# 3067M register map
File version: 1.0
Registers are 32-bit, access per field, reset 0x0 unless marked. A register's access mark holds for its fields unless they carry their own. Offsets are from the block's base; [hi:lo] are bit positions; {n}, {i} and the like mark numbered series.

## IOCMG_AON — IOCMG_AON peripheral interface
Base 0x147F0000
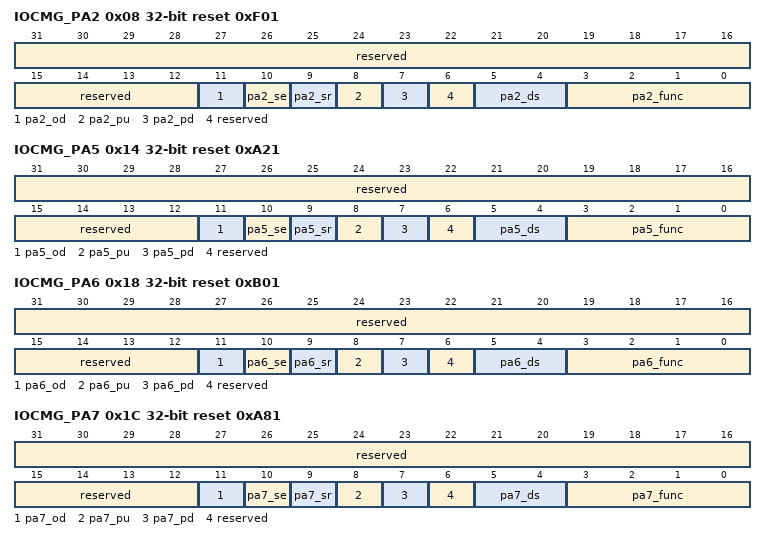
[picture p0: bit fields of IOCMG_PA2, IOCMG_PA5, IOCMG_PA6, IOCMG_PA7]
0x08 IOCMG_PA2 reset 0xF01 — IOCMG_PA2为PA2管脚控制寄存器。
  [31:12] reserved ro — 保留。
  [11] pa2_od rw — 管脚开漏输出控制。 0：打开； 1：关闭。
  [10] pa2_se rw — 管脚施密特输入控制。 0：关闭； 1：打开。
  [9] pa2_sr rw — 管脚电平转换速率控制。 0：快沿输出； 1：慢沿输出。
  [8] pa2_pu rw — 管脚上拉控制。 0：关闭； 1：打开。
  [7] pa2_pd rw — 管脚下拉控制。 0：关闭； 1：打开。
  [6] reserved ro — 保留。
  [5:4] pa2_ds rw — 管脚驱动能力选择（档位越高，驱动能力越大）。 00：档位1； 01：档位2； 10：档位3； 11：档位4。
  [3:0] pa2_func rw — 管脚复用功能选择。 具体复用功能请参见《3066H系列数据手册》。
0x14 IOCMG_PA5 reset 0xA21 — IOCMG_PA5为PA5管脚控制寄存器。
  [31:12] reserved ro — 保留。
  [11] pa5_od rw — 管脚开漏输出控制。 0：打开； 1：关闭。
  [10] pa5_se rw — 管脚施密特输入控制。 0：关闭； 1：打开。
  [9] pa5_sr rw — 管脚电平转换速率控制。 0：快沿输出； 1：慢沿输出。
  [8] pa5_pu rw — 管脚上拉控制。 0：关闭； 1：打开。
  [7] pa5_pd rw — 管脚下拉控制。 0：关闭； 1：打开。
  [6] reserved ro — 保留。
  [5:4] pa5_ds rw — 管脚驱动能力选择（档位越高，驱动能力越大）。 00：档位1； 01：档位2； 10：档位3； 11：档位4。
  [3:0] pa5_func rw — 管脚复用功能选择。 具体复用功能请参见《3066H系列数据手册》。
0x18 IOCMG_PA6 reset 0xB01 — IOCMG_PA6为PA6管脚控制寄存器。
  [31:12] reserved ro — 保留。
  [11] pa6_od rw — 管脚开漏输出控制。 0：打开； 1：关闭。
  [10] pa6_se rw — 管脚施密特输入控制。 0：关闭； 1：打开。
  [9] pa6_sr rw — 管脚电平转换速率控制。 0：快沿输出； 1：慢沿输出。
  [8] pa6_pu rw — 管脚上拉控制。 0：关闭； 1：打开。
  [7] pa6_pd rw — 管脚下拉控制。 0：关闭； 1：打开。
  [6] reserved ro — 保留。
  [5:4] pa6_ds rw — 管脚驱动能力选择（档位越高，驱动能力越大）。 00：档位1； 01：档位2； 10：档位3； 11：档位4。
  [3:0] pa6_func rw — 管脚复用功能选择。 具体复用功能请参见《3066H系列数据手册》。
0x1C IOCMG_PA7 reset 0xA81 — IOCMG_PA7为PA7管脚控制寄存器。
  [31:12] reserved ro — 保留。
  [11] pa7_od rw — 管脚开漏输出控制。 0：打开； 1：关闭。
  [10] pa7_se rw — 管脚施密特输入控制。 0：关闭； 1：打开。
  [9] pa7_sr rw — 管脚电平转换速率控制。 0：快沿输出； 1：慢沿输出。
  [8] pa7_pu rw — 管脚上拉控制。 0：关闭； 1：打开。
  [7] pa7_pd rw — 管脚下拉控制。 0：关闭； 1：打开。
  [6] reserved ro — 保留。
  [5:4] pa7_ds rw — 管脚驱动能力选择（档位越高，驱动能力越大）。 00：档位1； 01：档位2； 10：档位3； 11：档位4。
  [3:0] pa7_func rw — 管脚复用功能选择。 具体复用功能请参见《3066H系列数据手册》。
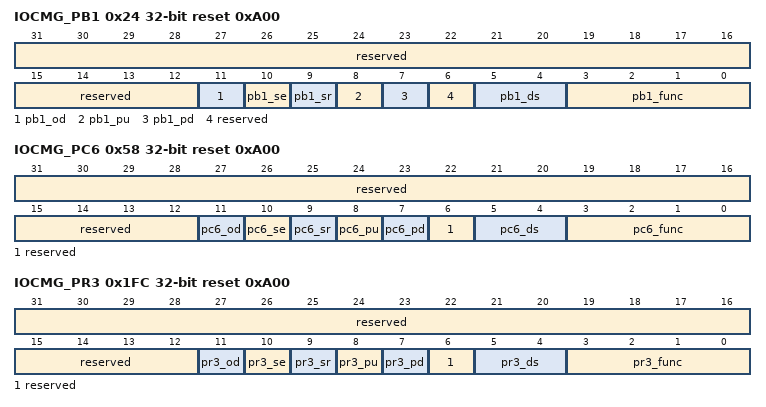
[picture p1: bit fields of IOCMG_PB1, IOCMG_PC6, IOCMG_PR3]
0x24 IOCMG_PB1 reset 0xA00 — IOCMG_PB1为PB1管脚控制寄存器。
  [31:12] reserved ro — 保留。
  [11] pb1_od rw — 管脚开漏输出控制。 0：打开； 1：关闭。
  [10] pb1_se rw — 管脚施密特输入控制。 0：关闭； 1：打开。
  [9] pb1_sr rw — 管脚电平转换速率控制。 0：快沿输出； 1：慢沿输出。
  [8] pb1_pu rw — 管脚上拉控制。 0：关闭； 1：打开。
  [7] pb1_pd rw — 管脚下拉控制。 0：关闭； 1：打开。
  [6] reserved ro — 保留。
  [5:4] pb1_ds rw — 管脚驱动能力选择（档位越高，驱动能力越大）。 00：档位1； 01：档位2； 10：档位3； 11：档位4。
  [3:0] pb1_func rw — 管脚复用功能选择。 具体复用功能请参见《3066H系列数据手册》。
0x58 IOCMG_PC6 reset 0xA00 — IOCMG_PC6为PC6管脚控制寄存器。
  [31:12] reserved ro — 保留。
  [11] pc6_od rw — 管脚开漏输出控制。 0：打开； 1：关闭。
  [10] pc6_se rw — 管脚施密特输入控制。 0：关闭； 1：打开。
  [9] pc6_sr rw — 管脚电平转换速率控制。 0：快沿输出； 1：慢沿输出。
  [8] pc6_pu rw — 管脚上拉控制。 0：关闭； 1：打开。
  [7] pc6_pd rw — 管脚下拉控制。 0：关闭； 1：打开。
  [6] reserved ro — 保留。
  [5:4] pc6_ds rw — 管脚驱动能力选择（档位越高，驱动能力越大）。 00：档位1； 01：档位2； 10：档位3； 11：档位4。
  [3:0] pc6_func rw — 管脚复用功能选择。 具体复用功能请参见《3066H系列数据手册》。
0x1FC IOCMG_PR3 reset 0xA00 — IOCMG_PR3为PR3管脚控制寄存器。
  [31:12] reserved ro — 保留。
  [11] pr3_od rw — 管脚开漏输出控制。 0：打开； 1：关闭。
  [10] pr3_se rw — 管脚施密特输入控制。 0：关闭； 1：打开。
  [9] pr3_sr rw — 管脚电平转换速率控制。 0：快沿输出； 1：慢沿输出。
  [8] pr3_pu rw — 管脚上拉控制。 0：关闭； 1：打开。
  [7] pr3_pd rw — 管脚下拉控制。 0：关闭； 1：打开。
  [6] reserved ro — 保留。
  [5:4] pr3_ds rw — 管脚驱动能力选择（档位越高，驱动能力越大）。 00：档位1； 01：档位2； 10：档位3； 11：档位4。
  [3:0] pr3_func rw — 管脚复用功能选择。 具体复用功能请参见《3066H系列数据手册》。

## IPCM — IPCM peripheral interface
Base 0x14820000
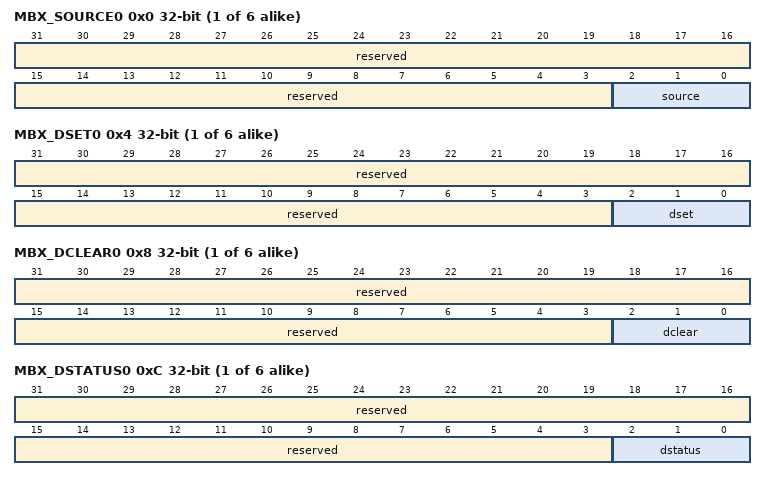
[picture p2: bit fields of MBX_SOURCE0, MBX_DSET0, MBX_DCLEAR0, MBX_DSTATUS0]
{0x0+0x40*i} MBX_SOURCE{i} (i=0..5) — MBX_SOURCE{i}为源处理器配置寄存器。
  [31:3] reserved ro — 保留。
  [2:0] source rw — 邮箱通道占用源处理器配置，可配置多个处理器共同占用此邮箱通道，每一bit对应一个占用通道的处理器。 配置后写相同值释放该通道邮箱，该邮箱除数据寄存器、模式寄存器之外的寄存器均清零，配置后写其他值无意义。位宽与宏定义IPC_CPU_NUM一致。（3067M为3）
{0x4+0x40*i} MBX_DSET{i} (i=0..5) — MBX_DSET{i}为目的处理器设置寄存器。
  [31:3] reserved ro — 保留。
  [2:0] dset wo — 邮箱通道目的处理器配置寄存器，即通信中断的接收处理器设置，可配置多个处理器同时接收中断，每一bit对应一个处理器。 0：无影响； 1：设置为目的处理器。
{0x8+0x40*i} MBX_DCLEAR{i} (i=0..5) — MBX_DCLEAR{i}为目的处理器清除寄存器。
  [31:3] reserved ro — 保留。
  [2:0] dclear wo — 邮箱通道目的处理器清除寄存器，每一bit对应一个处理器。 0：无影响； 1：清除。
{0xC+0x40*i} MBX_DSTATUS{i} ro (i=0..5) — MBX_DSTATUS{i}为目的处理器状态寄存器。
  [31:3] reserved — 保留。
  [2:0] dstatus — 邮箱通道目的处理器状态寄存器，每一bit对应一个处理器。
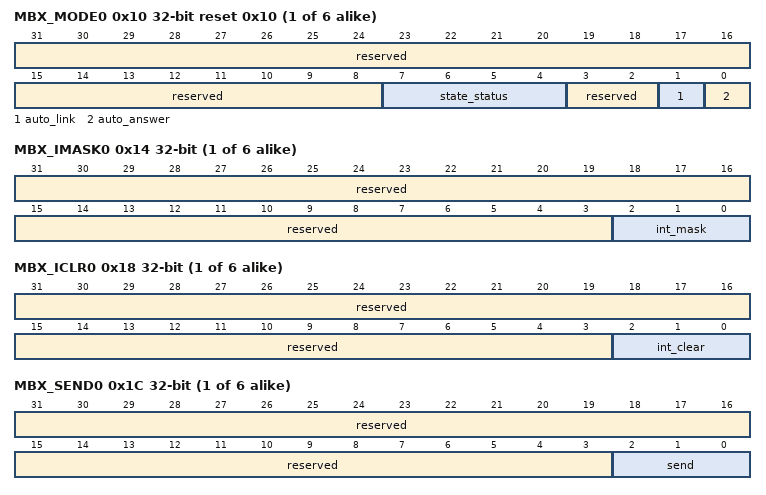
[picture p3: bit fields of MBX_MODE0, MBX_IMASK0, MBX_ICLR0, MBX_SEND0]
{0x10+0x40*i} MBX_MODE{i} reset 0x10 (i=0..5) — MBX_MODE{i}为邮箱通道模式状态机状态寄存器。
  [31:8] reserved ro — 保留。
  [7:4] state_status ro — 状态机状态。 0x1：空闲状态，邮箱空闲； 0x2：源状态，此状态下，邮箱通道已占用，还未发中断给目的处理器； 0x4：目的状态，此状态下，目的处理器收到源发中断，未全部清除或返回应答中断； 0x8：应答状态，此状态下，源收到应答中断未清除完毕； 其他：异常值。
  [3:2] reserved ro — 保留。
  [1] auto_link rw — Mailbox自动链接使能。 自动链接，将几个临近的Mailboxes链接在一起，从而可以将多个消息连续的发送出去，而不需要在消息与消息之间发送中断给源处理器。当所有信息都已经传递完毕，应答中断可以由一个目的处理器配置产生，也可以通过自动应答模式来产生。链的顺序是固定的，Mailbox 0链接到Mailbox 1，依次最高到最后一个邮箱，最后一个邮箱的自动链接功能配置无效。 0：禁止； 1：使能。
  [0] auto_answer rw — Mailbox自动应答使能。 自动应答，即当目的处理器中断被清除0后，mailbox自动发出一个回复中断给源处理器。 0：禁止； 1：使能。
{0x14+0x40*i} MBX_IMASK{i} (i=0..5) — MBX_IMASK{i}为处理器中断屏蔽寄存器。
  [31:3] reserved ro — 保留。
  [2:0] int_mask rw — 邮箱通道到处理器的中断屏蔽设置，每一bit对应一个处理器。 0：不屏蔽； 1：屏蔽。 位宽与宏定义IPC_CPU_NUM一致。（3067M为3）
{0x18+0x40*i} MBX_ICLR{i} (i=0..5) — MBX_ICLR{i}为处理器中断状态清除寄存器。
  [31:3] reserved ro — 保留。
  [2:0] int_clear rw write-clears — 邮箱通道到处理器屏蔽后中断状态，每一bit对应一个处理器，写1清除。 0：无中断； 1：有中断。 位宽与宏定义IPC_CPU_NUM一致。（3067M为3）
{0x1C+0x40*i} MBX_SEND{i} (i=0..5) — MBX_SEND{i}为发送寄存器。
  [31:3] reserved ro — 保留。
  [2:0] send rw — 中断发送寄存器，每一bit对应一个处理器。通信过程中，配置此寄存器，只置位bit有效。 当源发中断给目的时，send寄存器配置值与源寄存器值相等时发中断给目的处理器；当目的发应答中断给源时，send寄存器配置值与目的相等时发应答中断给源。自动链接时，被链接邮箱此寄存器不须配置；自动应答时，目的清除中断后，此寄存器自动置位，不须配置。 位宽与宏定义IPC_CPU_NUM一致。（3067M为3）
{0x20+0x40*i} MBX_DATA0-{i} rw (i=0..5) — MBX_DATA0-{i}为数据0寄存器。
  [31:0] data0 — 邮箱通道数据寄存器0。
{0x24+0x40*i} MBX_DATA1-{i} rw (i=0..5) — MBX_DATA1-{i}为数据1寄存器。
  [31:0] data1 — 邮箱通道数据寄存器1。
{0x28+0x40*i} MBX_DATA2-{i} rw (i=0..5) — MBX_DATA2-{i}为数据2寄存器。
  [31:0] data2 — 邮箱通道数据寄存器2。
{0x2C+0x40*i} MBX_DATA3-{i} rw (i=0..5) — MBX_DATA3-{i}为数据3寄存器。
  [31:0] data3 — 邮箱通道数据寄存器3。
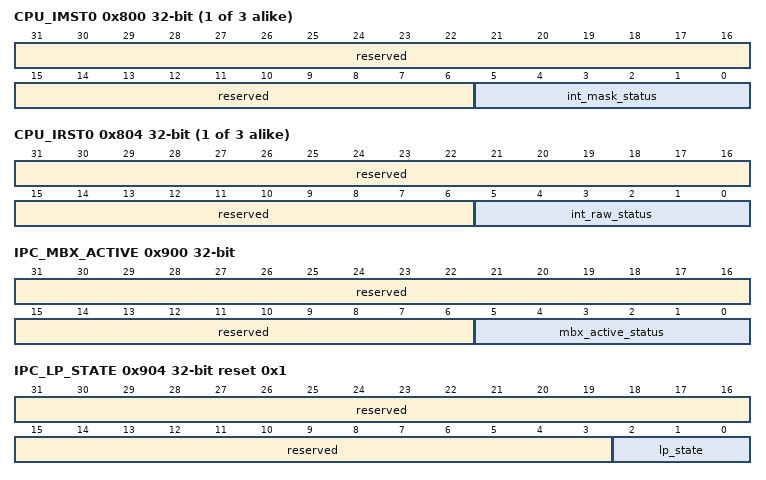
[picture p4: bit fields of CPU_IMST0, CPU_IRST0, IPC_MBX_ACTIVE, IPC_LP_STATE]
{0x800+8i} CPU_IMST{i} ro (i=0..2) — CPU_IMST{i}为中断屏蔽状态寄存器。
  [31:6] reserved — 保留。
  [5:0] int_mask_status — 处理器j屏蔽后的中断状态寄存器，每个bit对应一个邮箱通道。 0：无中断； 1：有中断。 位宽与宏定义IPC_MBX_NUM一致。（3066H为6）
{0x804+8i} CPU_IRST{i} ro (i=0..2) — CPU_IRST{i}为中断原始状态寄存器。
  [31:6] reserved — 保留。
  [5:0] int_raw_status — 处理器j原始中断状态寄存器，每个bit对应一个邮箱通道。 0：无中断； 1：有中断。 位宽与宏定义IPC_MBX_NUM一致。（3066H为6）
0x900 IPC_MBX_ACTIVE ro — IPC_MBX_ACTIVE为有效通道状态寄存器。
  [31:6] reserved — 保留。
  [5:0] mbx_active_status — 邮箱通道有效状态，每个bit对应一个邮箱通道。 0：空闲； 1：有效。 位宽与宏定义IPC_MBX_NUM一致。（3066H为6）
0x904 IPC_LP_STATE ro reset 0x1 — IPC_LP_STATE为低功耗状态寄存器。
  [31:3] reserved — 保留。
  [2:0] lp_state — 低功耗状态机状态。 000：空闲状态，模块复位状态； 001：工作状态，此状态表明功能模块处于工作状态； 010：低功耗请求状态，此状态表明外部有低功耗请求，模块需要做进入低功耗前的准备工作； 011：低功耗确认状态，此状态表明功能模块处于空闲，可以进入低功耗； 100：低功耗拒绝状态，此状态表明功能模块正忙无法进入低功耗； 101：等待退出低功耗状态，此状态等待外部送入低功耗退出请求； 110：等待确认退出低功耗状态，此状态等待功能模块给出退出低功耗响应信号； 其他：保留。
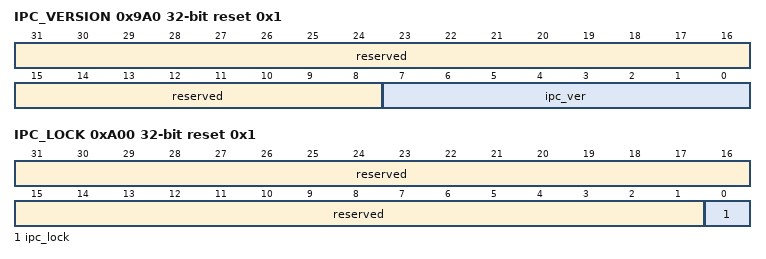
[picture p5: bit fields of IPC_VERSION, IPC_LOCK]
0x9A0 IPC_VERSION ro reset 0x1 — IPC_VERSION为IPC版本号寄存器。
  [31:8] reserved — 保留。
  [7:0] ipc_ver — IPC版本号寄存器，只读，版本号说明。 0x01：表示0.1版本； 其他：保留。
0xA00 IPC_LOCK reset 0x1 — IPC_LOCK为IPC锁定寄存器。
  [31:1] reserved ro — 保留。
  [0] ipc_lock rw — IPC寄存器锁定寄存器，复位值为1，向此寄存器写入0x5A5A5A5A，可解锁，写入其他值则锁定。 0：未锁定； 1：锁定。
